# STM32L062 register map
File version: 1.2
CPU: CM0+ r0p0, little endian, MPU, no FPU, 4 interrupt priority bits
Registers are 32-bit, read-write, reset 0x0 unless marked. A register's access mark holds for its fields unless they carry their own. Offsets are from the block's base; [hi:lo] are bit positions; {n}, {i} and the like mark numbered series; 'fields as' and 'values as' point back to an identical list.

## DAC — Digital-to-analog converter
Base 0x40007400
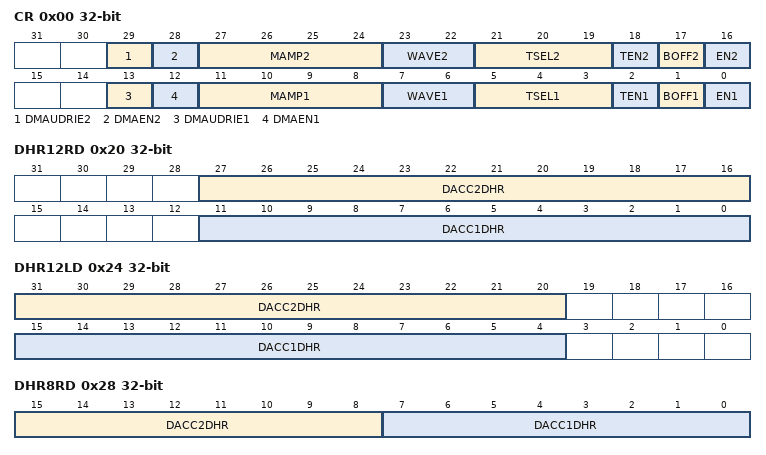
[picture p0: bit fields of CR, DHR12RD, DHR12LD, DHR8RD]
0x00 CR — control register
  [29] DMAUDRIE2 — DAC channel2 DMA underrun interrupt enable
  [28] DMAEN2 — DAC channel2 DMA enable
  [27:24] MAMP2 — DAC channel2 mask/amplitude selector
  [23:22] WAVE2 — DAC channel2 noise/triangle wave generation enable
  [21:19] TSEL2 — DAC channel2 trigger selection
  [18] TEN2 — DAC channel2 trigger enable
  [17] BOFF2 — DAC channel2 output buffer disable
  [16] EN2 — DAC channel2 enable
  [13] DMAUDRIE1 — DAC channel1 DMA Underrun Interrupt enable
  [12] DMAEN1 — DAC channel1 DMA enable
  [11:8] MAMP1 — DAC channel1 mask/amplitude selector
  [7:6] WAVE1 — DAC channel1 noise/triangle wave generation enable
  [5:3] TSEL1 — DAC channel1 trigger selection
  [2] TEN1 — DAC channel1 trigger enable
  [1] BOFF1 — DAC channel1 output buffer disable
  [0] EN1 — DAC channel1 enable
0x04 SWTRIGR wo — software trigger register
  [0] SWTRIG1 — DAC channel1 software trigger
0x08 DHR12R1 — channel1 12-bit right-aligned data holding register
  [11:0] DACC1DHR — DAC channel1 12-bit right-aligned data
0x0C DHR12L1 — channel1 12-bit left-aligned data holding register
  [15:4] DACC1DHR — DAC channel1 12-bit left-aligned data
0x10 DHR8R1 — channel1 8-bit right-aligned data holding register
  [7:0] DACC1DHR — DAC channel1 8-bit right-aligned data
0x14 DHR12R2 — channel2 12-bit right-aligned data holding register
  [11:0] DACC2DHR — DAC channel2 12-bit right-aligned data
0x18 DHR12L2 — channel2 12-bit left-aligned data holding register
  [15:4] DACC2DHR — DAC channel2 12-bit left-aligned data
0x1C DHR8R2 — channel2 8-bit right-aligned data holding register
  [7:0] DACC2DHR — DAC channel2 8-bit right-aligned data
0x20 DHR12RD — Dual DAC 12-bit right-aligned data holding register
  [27:16] DACC2DHR — DAC channel2 12-bit right-aligned data
  [11:0] DACC1DHR — DAC channel1 12-bit right-aligned data
0x24 DHR12LD — Dual DAC 12-bit left-aligned data holding register
  [31:20] DACC2DHR — DAC channel2 12-bit left-aligned data
  [15:4] DACC1DHR — DAC channel1 12-bit left-aligned data
0x28 DHR8RD — Dual DAC 8-bit right-aligned data holding register
  [15:8] DACC2DHR — DAC channel2 8-bit right-aligned data
  [7:0] DACC1DHR — DAC channel1 8-bit right-aligned data
0x2C DOR1 ro — channel1 data output register
  [11:0] DACC1DOR — DAC channel1 data output
0x30 DOR2 ro — channel2 data output register
  [11:0] DACC2DOR — DAC channel2 data output
0x34 SR — status register
  [13] DMAUDR1 — DAC channel1 DMA underrun flag

## DMA1 — Direct memory access controller
Base 0x40020000
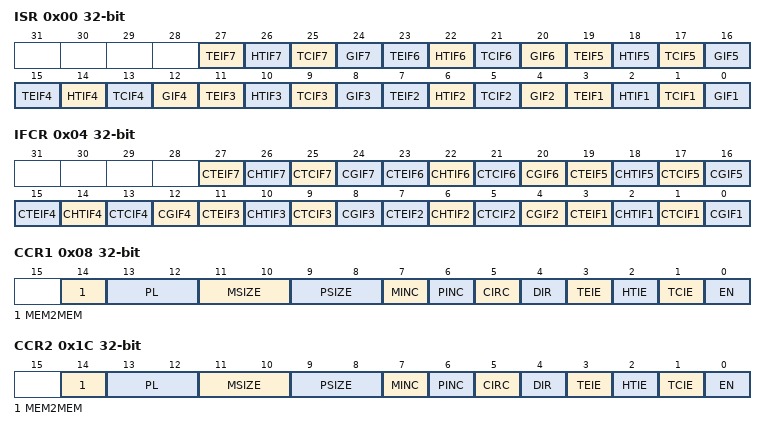
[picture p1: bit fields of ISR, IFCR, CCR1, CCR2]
0x00 ISR ro — interrupt status register
  [4n-1] TEIF{n} (n=1..7) — Channel x transfer error flag (x = 1 ..7)
  [4n-2] HTIF{n} (n=1..7) — Channel x half transfer flag (x = 1 ..7)
  [4n-3] TCIF{n} (n=1..7) — Channel x transfer complete flag (x = 1 ..7)
  [4n-4] GIF{n} (n=1..7) — Channel x global interrupt flag (x = 1 ..7)
0x04 IFCR wo — interrupt flag clear register
  [4n-1] CTEIF{n} (n=1..7) — Channel x transfer error clear (x = 1 ..7)
  [4n-2] CHTIF{n} (n=1..7) — Channel x half transfer clear (x = 1 ..7)
  [4n-3] CTCIF{n} (n=1..7) — Channel x transfer complete clear (x = 1 ..7)
  [4n-4] CGIF{n} (n=1..7) — Channel x global interrupt clear (x = 1 ..7)
0x08 CCR1 — channel x configuration register
  [14] MEM2MEM — Memory to memory mode
  [13:12] PL — Channel priority level
  [11:10] MSIZE — Memory size
  [9:8] PSIZE — Peripheral size
  [7] MINC — Memory increment mode
  [6] PINC — Peripheral increment mode
  [5] CIRC — Circular mode
  [4] DIR — Data transfer direction
  [3] TEIE — Transfer error interrupt enable
  [2] HTIE — Half transfer interrupt enable
  [1] TCIE — Transfer complete interrupt enable
  [0] EN — Channel enable
0x0C CNDTR1 — channel x number of data register
  [15:0] NDT — Number of data to transfer
0x10 CPAR1 — channel x peripheral address register
  [31:0] PA — Peripheral address
{0x0+0x14*i} CMAR{i} (i=1..7) — channel x memory address register
  [31:0] MA — Memory address
0x1C CCR2 — channel x configuration register
  fields as CCR1
0x20 CNDTR2 — channel x number of data register
  [15:0] NDT — Number of data to transfer
0x24 CPAR2 — channel x peripheral address register
  [31:0] PA — Peripheral address
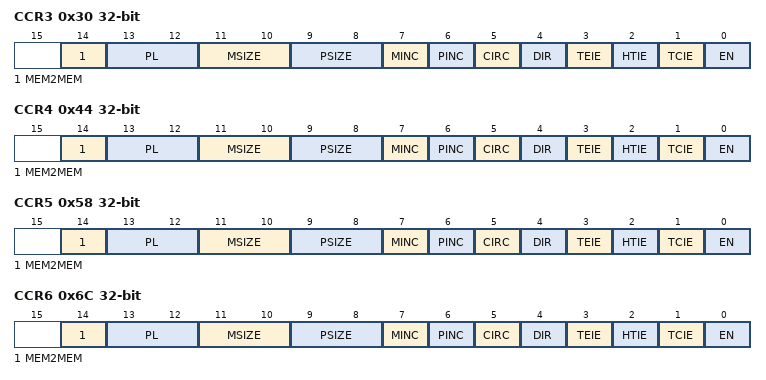
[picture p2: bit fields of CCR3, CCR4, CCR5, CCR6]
0x30 CCR3 — channel x configuration register
  fields as CCR1
0x34 CNDTR3 — channel x number of data register
  [15:0] NDT — Number of data to transfer
0x38 CPAR3 — channel x peripheral address register
  [31:0] PA — Peripheral address
0x44 CCR4 — channel x configuration register
  fields as CCR1
0x48 CNDTR4 — channel x number of data register
  [15:0] NDT — Number of data to transfer
0x4C CPAR4 — channel x peripheral address register
  [31:0] PA — Peripheral address
0x58 CCR5 — channel x configuration register
  fields as CCR1
0x5C CNDTR5 — channel x number of data register
  [15:0] NDT — Number of data to transfer
0x60 CPAR5 — channel x peripheral address register
  [31:0] PA — Peripheral address
0x6C CCR6 — channel x configuration register
  fields as CCR1
0x70 CNDTR6 — channel x number of data register
  [15:0] NDT — Number of data to transfer
0x74 CPAR6 — channel x peripheral address register
  [31:0] PA — Peripheral address
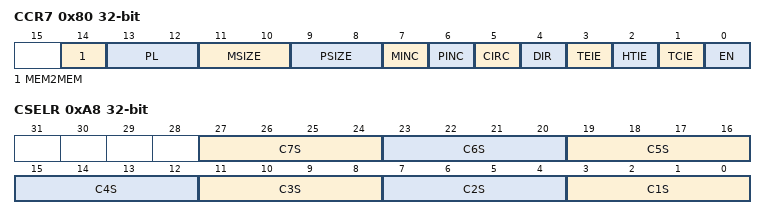
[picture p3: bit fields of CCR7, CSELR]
0x80 CCR7 — channel x configuration register
  fields as CCR1
0x84 CNDTR7 — channel x number of data register
  [15:0] NDT — Number of data to transfer
0x88 CPAR7 — channel x peripheral address register
  [31:0] PA — Peripheral address
0xA8 CSELR — channel selection register
  [4n-1:4n-4] C{n}S (n=1..7) — DMA channel {n} selection
